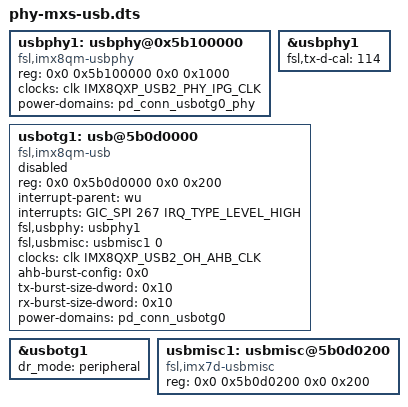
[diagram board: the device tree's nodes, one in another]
//  @   arch/arm64/boot/dts/freescale/fsl-imx8dx.dtsi

//  @ ./drivers/usb/phy/phy-mxs-usb.c:253:	{ .compatible = "fsl,imx7ulp-usbphy", .data = &imx7ulp_phy_data, },
//  @ ./drivers/usb/phy/phy-mxs-usb.c:254:	{ .compatible = "fsl,imx6ul-usbphy", .data = &imx6sx_phy_data, },
//  @ ./drivers/usb/phy/phy-mxs-usb.c:260:	{ .compatible = "fsl,imx6ul-usbphy", .data = &imx6ul_phy_data, },
//  @ ./drivers/usb/phy/phy-mxs-usb.c:258:	{ .compatible = "fsl,imx23-usbphy", .data = &imx23_phy_data, },
usbphy1: usbphy@0x5b100000 {
    compatible = "fsl,imx8qm-usbphy", "fsl,imx7ulp-usbphy", "fsl,imx6ul-usbphy", "fsl,imx23-usbphy";
    reg = <0x0 0x5b100000 0x0 0x1000>;
    clocks = <&clk IMX8QXP_USB2_PHY_IPG_CLK>;
    power-domains = <&pd_conn_usbotg0_phy>;
};

//  @   arch/arm64/boot/dts/freescale/fsl-imx8qxp-autolink-tsu.dtsi
&usbphy1 {
	fsl,tx-d-cal = <114>;
};


//  @   drivers/usb/chipidea/ci_hdrc_imx.c:106
usbotg1: usb@5b0d0000 {
    compatible = "fsl,imx8qm-usb", "fsl,imx27-usb";
    reg = <0x0 0x5b0d0000 0x0 0x200>;
    interrupt-parent = <&wu>;
    interrupts = <GIC_SPI 267 IRQ_TYPE_LEVEL_HIGH>;
    fsl,usbphy = <&usbphy1>;
    fsl,usbmisc = <&usbmisc1 0>;
    clocks = <&clk IMX8QXP_USB2_OH_AHB_CLK>;
    ahb-burst-config = <0x0>;
    tx-burst-size-dword = <0x10>;
    rx-burst-size-dword = <0x10>;
    #stream-id-cells = <1>;
    power-domains = <&pd_conn_usbotg0>;
    status = "disabled";
};

//  @   arch/arm64/boot/dts/freescale/fsl-imx8qxp-autolink-tsu.dtsi
&usbotg1 {
	dr_mode = "peripheral";
	status = "okay";
};


usbmisc1: usbmisc@5b0d0200 {
    #index-cells = <1>;
    compatible = "fsl,imx7d-usbmisc", "fsl,imx6q-usbmisc";
    reg = <0x0 0x5b0d0200 0x0 0x200>;
};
